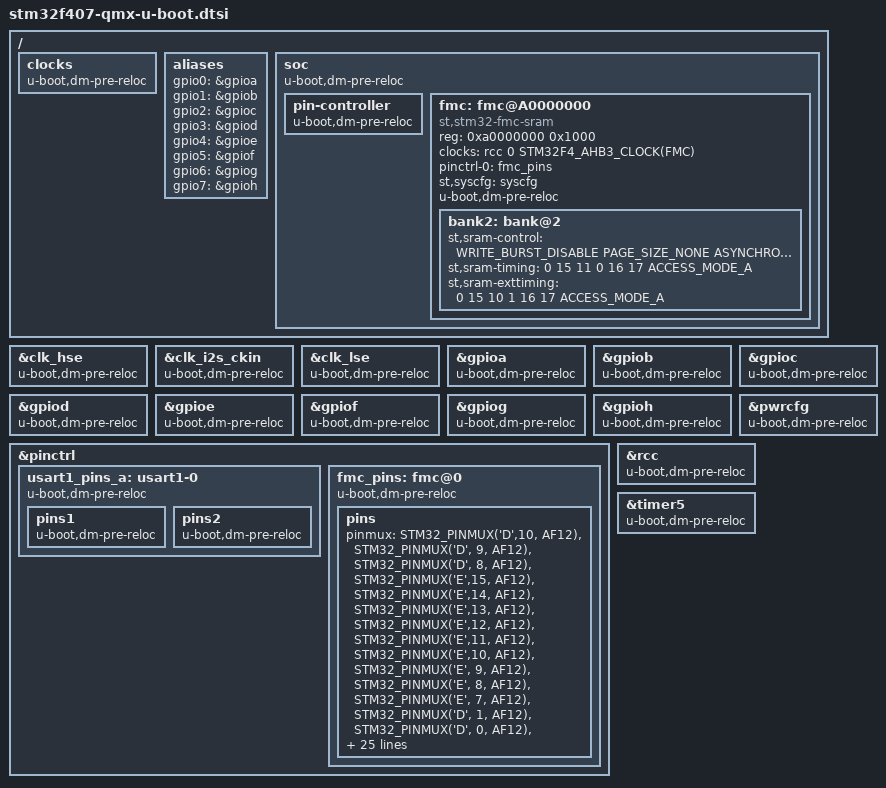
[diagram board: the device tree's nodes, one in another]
// SPDX-License-Identifier: GPL-2.0+
/*
 * Copyright (C) 2017, STMicroelectronics - All Rights Reserved
 * Author(s): Patrice Chotard, <patrice.chotard@foss.st.com> for STMicroelectronics.
 */

#include <dt-bindings/memory/stm32-sram.h>
/{
	clocks {
		u-boot,dm-pre-reloc;
	};

	aliases {
		/* Aliases for gpios so as to use sequence */
		gpio0 = &gpioa;
		gpio1 = &gpiob;
		gpio2 = &gpioc;
		gpio3 = &gpiod;
		gpio4 = &gpioe;
		gpio5 = &gpiof;
		gpio6 = &gpiog;
		gpio7 = &gpioh;
	};

	soc {
		u-boot,dm-pre-reloc;
		pin-controller {
			u-boot,dm-pre-reloc;
		};

		fmc: fmc@A0000000 {
			compatible = "st,stm32-fmc-sram";
			reg = <0xa0000000 0x1000>;
			clocks = <&rcc 0 STM32F4_AHB3_CLOCK(FMC)>;
			pinctrl-0 = <&fmc_pins>;
			pinctrl-names = "default";
			st,syscfg = <&syscfg>;
			u-boot,dm-pre-reloc;

			/*
			 * Memory configuration from sdram datasheet
			 * IS62WV51216
			 */
			bank2: bank@2 {
					st,sram-control = /bits/ 8 <WRITE_BURST_DISABLE
							    PAGE_SIZE_NONE
							    ASYNCHRONOUS_WAIT_DISABLE
							    EXTENDED_MODE_ENABLE
							    WAIT_SIGNAL_DISABLE
							    WRITE_OPERATION_ENABLE
							    WAIT_TIMING_BEFORE_WS
							    WRAP_MODE_DISABLE
								WAIT_SIGNAL_POLARITY_LOW
								BURST_ACCESS_MODE_DISABLE
								NORSRAM_MEM_BUS_WIDTH_16
								MEMORY_TYPE_SRAM
								DATA_ADDRESS_MUX_DISABLE>;
			       st,sram-timing = /bits/ 8 <0
							   15
							   11
							   0
							   16
							   17 ACCESS_MODE_A>;
					st,sram-exttiming = /bits/ 8 <0
							   15
							   10
							   1
							   16
							   17 ACCESS_MODE_A>;
		       };
		};
	};
};

&clk_hse {
	u-boot,dm-pre-reloc;
};

&clk_i2s_ckin {
	u-boot,dm-pre-reloc;
};

&clk_lse {
	u-boot,dm-pre-reloc;
};

&gpioa {
	u-boot,dm-pre-reloc;
};

&gpiob {
	u-boot,dm-pre-reloc;
};

&gpioc {
	u-boot,dm-pre-reloc;
};

&gpiod {
	u-boot,dm-pre-reloc;
};

&gpioe {
	u-boot,dm-pre-reloc;
};

&gpiof {
	u-boot,dm-pre-reloc;
};

&gpiog {
	u-boot,dm-pre-reloc;
};

&gpioh {
	u-boot,dm-pre-reloc;
};

&pinctrl {
	usart1_pins_a: usart1-0	{
		u-boot,dm-pre-reloc;
		pins1 {
			u-boot,dm-pre-reloc;
		};
		pins2 {
			u-boot,dm-pre-reloc;
		};
	};

	fmc_pins: fmc@0 {
		u-boot,dm-pre-reloc;
		pins
		{
			pinmux = <STM32_PINMUX('D',10, AF12)>, /* D15 */
				 <STM32_PINMUX('D', 9, AF12)>, /* D14 */
				 <STM32_PINMUX('D', 8, AF12)>, /* D13 */
				 <STM32_PINMUX('E',15, AF12)>, /* D12 */
				 <STM32_PINMUX('E',14, AF12)>, /* D11 */
				 <STM32_PINMUX('E',13, AF12)>, /* D10 */
				 <STM32_PINMUX('E',12, AF12)>, /* D09 */
				 <STM32_PINMUX('E',11, AF12)>, /* D08 */
				 <STM32_PINMUX('E',10, AF12)>, /* D07 */
				 <STM32_PINMUX('E', 9, AF12)>, /* D06 */
				 <STM32_PINMUX('E', 8, AF12)>, /* D05 */
				 <STM32_PINMUX('E', 7, AF12)>, /* D04 */
				 <STM32_PINMUX('D', 1, AF12)>, /* D03 */
				 <STM32_PINMUX('D', 0, AF12)>, /* D02 */
				 <STM32_PINMUX('D',15, AF12)>, /* D01 */
				 <STM32_PINMUX('D',14, AF12)>, /* D00 */

				 <STM32_PINMUX('E', 0, AF12)>, /* NBL0 */
				 <STM32_PINMUX('E', 1, AF12)>, /* NBL1 */

				 <STM32_PINMUX('G', 5, AF12)>, /* A15 */
				 <STM32_PINMUX('G', 4, AF12)>, /* A14 */
				 <STM32_PINMUX('G', 3, AF12)>, /* A13 */
				 <STM32_PINMUX('G', 2, AF12)>, /* A12 */
				 <STM32_PINMUX('G', 1, AF12)>, /* A11 */
				 <STM32_PINMUX('G', 0, AF12)>, /* A10 */
				 <STM32_PINMUX('F',15, AF12)>, /* A09 */
				 <STM32_PINMUX('F',14, AF12)>, /* A08 */
				 <STM32_PINMUX('F',13, AF12)>, /* A07 */
				 <STM32_PINMUX('F',12, AF12)>, /* A06 */
				 <STM32_PINMUX('F', 5, AF12)>, /* A05 */
				 <STM32_PINMUX('F', 4, AF12)>, /* A04 */
				 <STM32_PINMUX('F', 3, AF12)>, /* A03 */
				 <STM32_PINMUX('F', 2, AF12)>, /* A02 */
				 <STM32_PINMUX('F', 1, AF12)>, /* A01 */
				 <STM32_PINMUX('F', 0, AF12)>, /* A00 */

				 <STM32_PINMUX('D', 4, AF12)>, /* NOE */
				 <STM32_PINMUX('D', 5, AF12)>, /* NWE */
				 <STM32_PINMUX('G',10, AF12)>; /* NE3 */
			slew-rate = <2>;
			u-boot,dm-pre-reloc;
		};
	};
};

&pwrcfg {
	u-boot,dm-pre-reloc;
};

&rcc {
	u-boot,dm-pre-reloc;
};

&timer5 {
	u-boot,dm-pre-reloc;
};
